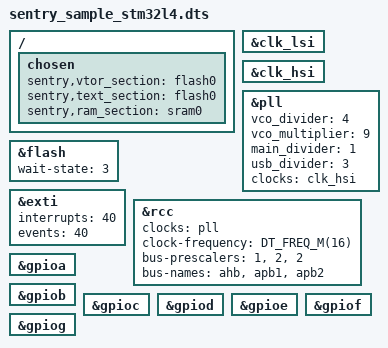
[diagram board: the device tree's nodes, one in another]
/*
 * Copyright (c) 2023,Ledger SAS
 *
 * SPDX-License-Identifier: Apache-2.0
 */

/dts-v1/;

#include <st/l4/stm32l476Xg.dtsi>

/{
	chosen {
		sentry,vtor_section = <&flash0>;
		sentry,text_section = <&flash0>;
		sentry,ram_section = <&sram0>;
	};

};

&clk_lsi {
	status = "okay";
};

&clk_hsi {
	status = "okay";
};

&pll {
	vco_divider = <4>;
	vco_multiplier = <9>;
	main_divider = <1>;
	usb_divider = <3>;
	clocks = <&clk_hsi>;
	status = "okay";
};

&flash {
	wait-state = <3>; /* According to voltage supply and sysclock */
	status = "okay";
};

&exti {
	interrupts = <40>;
	events = <40>;
	status = "okay";
};

&rcc {
	clocks = <&pll>;
	clock-frequency = <DT_FREQ_M(16)>;
	bus-prescalers = <1>, <2>, <2>;
	bus-names = "ahb", "apb1", "apb2";
	status = "okay";
};

&gpioa {
	status = "okay";
};

&gpiob {
	status = "okay";
};

&gpioc {
	status = "okay";
};

&gpiod {
	status = "okay";
};

&gpioe {
	status = "okay";
};

&gpiof {
	status = "okay";
};

&gpiog {
	status = "okay";
};
